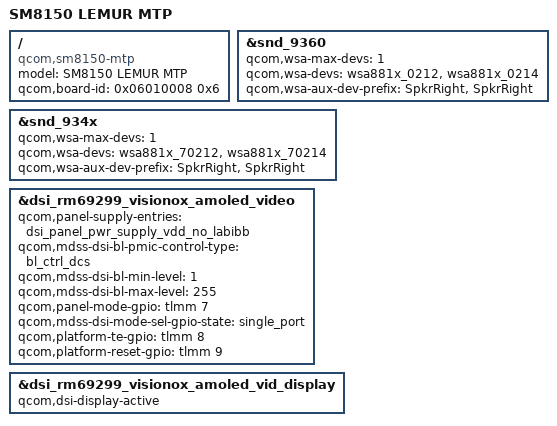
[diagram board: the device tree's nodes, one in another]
/* Copyright (c) 2020, The Linux Foundation. All rights reserved.
 *
 * This program is free software; you can redistribute it and/or modify
 * it under the terms of the GNU General Public License version 2 and
 * only version 2 as published by the Free Software Foundation.
 *
 * This program is distributed in the hope that it will be useful,
 * but WITHOUT ANY WARRANTY; without even the implied warranty of
 * MERCHANTABILITY or FITNESS FOR A PARTICULAR PURPOSE.  See the
 * GNU General Public License for more details.
 */

/dts-v1/;
/plugin/;

#include <dt-bindings/clock/qcom,camcc-sm8150.h>

#include "sm8150-mtp.dtsi"

#include "sdx5xm-external-soc.dtsi"
#include "sm8150-lemur.dtsi"

/ {
	model = "SM8150 LEMUR MTP";
	compatible = "qcom,sm8150-mtp", "qcom,sm8150", "qcom,mtp";
	qcom,board-id = <0x06010008 0x6>;
};

&snd_9360 {
	qcom,wsa-max-devs = <1>;
	qcom,wsa-devs = <&wsa881x_0212>, <&wsa881x_0214>;
	qcom,wsa-aux-dev-prefix = "SpkrRight", "SpkrRight";
};

&snd_934x {
	qcom,wsa-max-devs = <1>;
	qcom,wsa-devs = <&wsa881x_70212>, <&wsa881x_70214>;
	qcom,wsa-aux-dev-prefix = "SpkrRight", "SpkrRight";
};

&dsi_rm69299_visionox_amoled_video {
	qcom,panel-supply-entries = <&dsi_panel_pwr_supply_vdd_no_labibb>;
	qcom,mdss-dsi-bl-pmic-control-type = "bl_ctrl_dcs";
	qcom,mdss-dsi-bl-min-level = <1>;
	qcom,mdss-dsi-bl-max-level = <255>;
	qcom,panel-mode-gpio = <&tlmm 7 0>;
	qcom,mdss-dsi-mode-sel-gpio-state = "single_port";
	qcom,platform-te-gpio = <&tlmm 8 0>;
	qcom,platform-reset-gpio = <&tlmm 9 0>;
};

&dsi_rm69299_visionox_amoled_vid_display {
	qcom,dsi-display-active;
};
